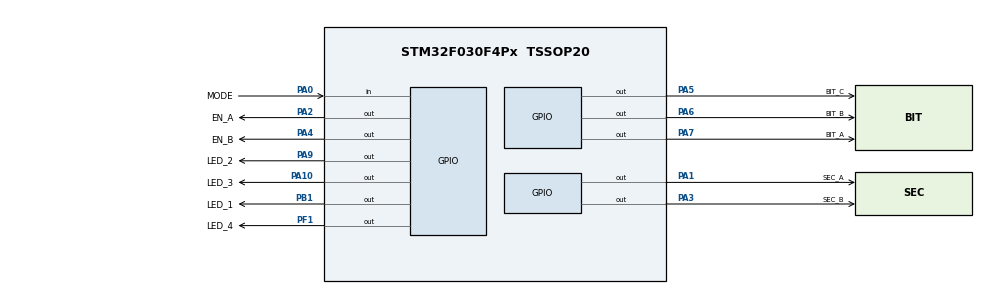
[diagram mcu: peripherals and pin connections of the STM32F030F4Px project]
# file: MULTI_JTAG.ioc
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Mcu.Family=STM32F0
Mcu.Name=STM32F030F4Px
Mcu.Package=TSSOP20
PA0.GPIO_Label=MODE
PA0.Signal=GPIO_Input
PA1.GPIO_Label=SEC_A
PA1.GPIO_PuPd=GPIO_PULLUP
PA1.Signal=GPIO_Output
PA10.GPIO_Label=LED_3
PA10.Signal=GPIO_Output
PA13.Mode=Serial_Wire
PA13.Signal=SYS_SWDIO
PA14.Mode=Serial_Wire
PA14.Signal=SYS_SWCLK
PA2.GPIO_Label=EN_A
PA2.GPIO_PuPd=GPIO_PULLUP
PA2.Signal=GPIO_Output
PA3.GPIO_Label=SEC_B
PA3.GPIO_PuPd=GPIO_PULLUP
PA3.Signal=GPIO_Output
PA4.GPIO_Label=EN_B
PA4.GPIO_PuPd=GPIO_PULLUP
PA4.Signal=GPIO_Output
PA5.GPIO_Label=BIT_C
PA5.GPIO_PuPd=GPIO_PULLUP
PA5.Signal=GPIO_Output
PA6.GPIO_Label=BIT_B
PA6.GPIO_PuPd=GPIO_PULLUP
PA6.Signal=GPIO_Output
PA7.GPIO_Label=BIT_A
PA7.GPIO_PuPd=GPIO_PULLUP
PA7.Signal=GPIO_Output
PA9.GPIO_Label=LED_2
PA9.Signal=GPIO_Output
PB1.GPIO_Label=LED_1
PB1.Signal=GPIO_Output
PF1-OSC_OUT.GPIO_Label=LED_4
PF1-OSC_OUT.Signal=GPIO_Output
ProjectManager.HeapSize=0x200
ProjectManager.StackSize=0x400
ProjectManager.TargetToolchain=MDK-ARM V5.32
RCC.AHBCLKDivider=RCC_SYSCLK_DIV2
RCC.AHBFreq_Value=4000000
RCC.APB1Freq_Value=4000000
RCC.APB1TimFreq_Value=4000000
RCC.HCLKFreq_Value=4000000
board=custom

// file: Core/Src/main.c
/* USER CODE BEGIN Header */
/**
  ******************************************************************************
  * @file           : main.c
  * @brief          : Main program body
  ******************************************************************************
  * @attention
  *
  * Copyright (c) 2023 STMicroelectronics.
  * All rights reserved.
  *
  * This software is licensed under terms that can be found in the LICENSE file
  * in the root directory of this software component.
  * If no LICENSE file comes with this software, it is provided AS-IS.
  *
  ******************************************************************************
  */
/* USER CODE END Header */
#include "AppProc.h"

void SystemClock_Config(void);
static void MX_GPIO_Init(void);

int main(void)
{

  /* MCU Configuration--------------------------------------------------------*/

  /* Reset of all peripherals, Initializes the Flash interface and the Systick. */
  HAL_Init();

  /* Configure the system clock */
  SystemClock_Config();

  /* Initialize all configured peripherals */
  MX_GPIO_Init();
  /* USER CODE BEGIN 2 */
  StartingAnimation();
  ReadDataOption();
  /* USER CODE END 2 */

  /* Infinite loop */
  while (1)
  {

    /* USER CODE BEGIN 3 */
    ButtonProcess();
    CheckTimeBackupData();

  }
  /* USER CODE END 3 */
}

void SystemClock_Config(void)
{
  RCC_OscInitTypeDef RCC_OscInitStruct = {0};
  RCC_ClkInitTypeDef RCC_ClkInitStruct = {0};

  /** Initializes the RCC Oscillators according to the specified parameters
  * in the RCC_OscInitTypeDef structure.
  */
  RCC_OscInitStruct.OscillatorType = RCC_OSCILLATORTYPE_HSI;
  RCC_OscInitStruct.HSIState = RCC_HSI_ON;
  RCC_OscInitStruct.HSICalibrationValue = RCC_HSICALIBRATION_DEFAULT;
  RCC_OscInitStruct.PLL.PLLState = RCC_PLL_NONE;
  if (HAL_RCC_OscConfig(&RCC_OscInitStruct) != HAL_OK)
  {
    Error_Handler();
  }

  /** Initializes the CPU, AHB and APB buses clocks
  */
  RCC_ClkInitStruct.ClockType = RCC_CLOCKTYPE_HCLK|RCC_CLOCKTYPE_SYSCLK
                              |RCC_CLOCKTYPE_PCLK1;
  RCC_ClkInitStruct.SYSCLKSource = RCC_SYSCLKSOURCE_HSI;
  RCC_ClkInitStruct.AHBCLKDivider = RCC_SYSCLK_DIV2;
  RCC_ClkInitStruct.APB1CLKDivider = RCC_HCLK_DIV1;

  if (HAL_RCC_ClockConfig(&RCC_ClkInitStruct, FLASH_LATENCY_0) != HAL_OK)
  {
    Error_Handler();
  }
}

static void MX_GPIO_Init(void)
{
  GPIO_InitTypeDef GPIO_InitStruct = {0};

  /* GPIO Ports Clock Enable */
  __HAL_RCC_GPIOF_CLK_ENABLE();
  __HAL_RCC_GPIOA_CLK_ENABLE();
  __HAL_RCC_GPIOB_CLK_ENABLE();

  /*Configure GPIO pin Output Level */
  HAL_GPIO_WritePin(LED_4_GPIO_Port, LED_4_Pin, GPIO_PIN_RESET);

  /*Configure GPIO pin Output Level */
  HAL_GPIO_WritePin(GPIOA, SEC_A_Pin|EN_A_Pin|SEC_B_Pin|EN_B_Pin
                          |BIT_C_Pin|BIT_B_Pin|BIT_A_Pin|LED_2_Pin
                          |LED_3_Pin, GPIO_PIN_RESET);

  /*Configure GPIO pin Output Level */
  HAL_GPIO_WritePin(LED_1_GPIO_Port, LED_1_Pin, GPIO_PIN_RESET);

  /*Configure GPIO pin : LED_4_Pin */
  GPIO_InitStruct.Pin = LED_4_Pin;
  GPIO_InitStruct.Mode = GPIO_MODE_OUTPUT_PP;
  GPIO_InitStruct.Pull = GPIO_NOPULL;
  GPIO_InitStruct.Speed = GPIO_SPEED_FREQ_LOW;
  HAL_GPIO_Init(LED_4_GPIO_Port, &GPIO_InitStruct);

  /*Configure GPIO pin : MODE_Pin */
  GPIO_InitStruct.Pin = MODE_Pin;
  GPIO_InitStruct.Mode = GPIO_MODE_INPUT;
  GPIO_InitStruct.Pull = GPIO_NOPULL;
  HAL_GPIO_Init(MODE_GPIO_Port, &GPIO_InitStruct);

  /*Configure GPIO pins : SEC_A_Pin EN_A_Pin SEC_B_Pin EN_B_Pin
                           BIT_C_Pin BIT_B_Pin BIT_A_Pin */
  GPIO_InitStruct.Pin = SEC_A_Pin|EN_A_Pin|SEC_B_Pin|EN_B_Pin
                          |BIT_C_Pin|BIT_B_Pin|BIT_A_Pin;
  GPIO_InitStruct.Mode = GPIO_MODE_OUTPUT_PP;
  GPIO_InitStruct.Pull = GPIO_PULLUP;
  GPIO_InitStruct.Speed = GPIO_SPEED_FREQ_LOW;
  HAL_GPIO_Init(GPIOA, &GPIO_InitStruct);

  /*Configure GPIO pin : LED_1_Pin */
  GPIO_InitStruct.Pin = LED_1_Pin;
  GPIO_InitStruct.Mode = GPIO_MODE_OUTPUT_PP;
  GPIO_InitStruct.Pull = GPIO_NOPULL;
  GPIO_InitStruct.Speed = GPIO_SPEED_FREQ_LOW;
  HAL_GPIO_Init(LED_1_GPIO_Port, &GPIO_InitStruct);

  /*Configure GPIO pins : LED_2_Pin LED_3_Pin */
  GPIO_InitStruct.Pin = LED_2_Pin|LED_3_Pin;
  GPIO_InitStruct.Mode = GPIO_MODE_OUTPUT_PP;
  GPIO_InitStruct.Pull = GPIO_NOPULL;
  GPIO_InitStruct.Speed = GPIO_SPEED_FREQ_LOW;
  HAL_GPIO_Init(GPIOA, &GPIO_InitStruct);

}

void Error_Handler(void)
{
  __disable_irq();
  while (1)
  {
  }
}
